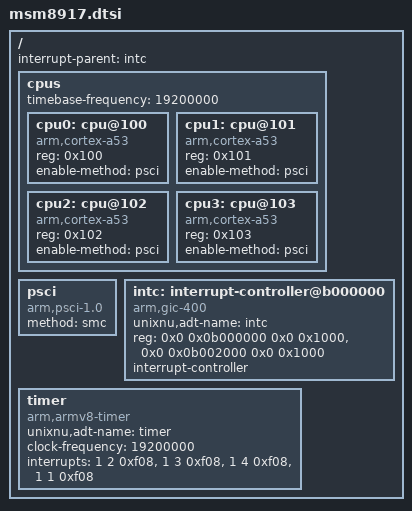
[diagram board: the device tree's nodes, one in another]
// Minimal MSM8917 SoC description for UniXNU device-tree assembly.
// Peripheral nodes are added as drivers are ported. Values come from
// UniXNU-rolex docs/hardware-inventory.md and the stock rolex DTB.
// This file is a scaffold: it is not yet a complete board description.

/ {
    #address-cells = <2>;
    #size-cells = <2>;
    interrupt-parent = <&intc>;

    cpus {
        #address-cells = <1>;
        #size-cells = <0>;
        // From the stock rolex DT timer node: clock-frequency = 0x0124f800.
        timebase-frequency = <19200000>;

        cpu0: cpu@100 {
            device_type = "cpu";
            compatible = "arm,cortex-a53";
            reg = <0x100>;
            enable-method = "psci";
        };
        cpu1: cpu@101 {
            device_type = "cpu";
            compatible = "arm,cortex-a53";
            reg = <0x101>;
            enable-method = "psci";
        };
        cpu2: cpu@102 {
            device_type = "cpu";
            compatible = "arm,cortex-a53";
            reg = <0x102>;
            enable-method = "psci";
        };
        cpu3: cpu@103 {
            device_type = "cpu";
            compatible = "arm,cortex-a53";
            reg = <0x103>;
            enable-method = "psci";
        };
    };

    psci {
        compatible = "arm,psci-1.0";
        method = "smc";
    };

    intc: interrupt-controller@b000000 {
        compatible = "arm,gic-400";
        unixnu,adt-name = "intc";
        reg = <0x0 0x0b000000 0x0 0x1000>,
              <0x0 0x0b002000 0x0 0x1000>;
        interrupt-controller;
        #interrupt-cells = <3>;
        #address-cells = <0>;
    };

    timer {
        compatible = "arm,armv8-timer";
        unixnu,adt-name = "timer";
        clock-frequency = <19200000>;
        // Stock rolex DT: PPI 1..4, not the ARM default 13/14/11/10.
        interrupts = <1 2 0xf08>,
                     <1 3 0xf08>,
                     <1 4 0xf08>,
                     <1 1 0xf08>;
    };
};
